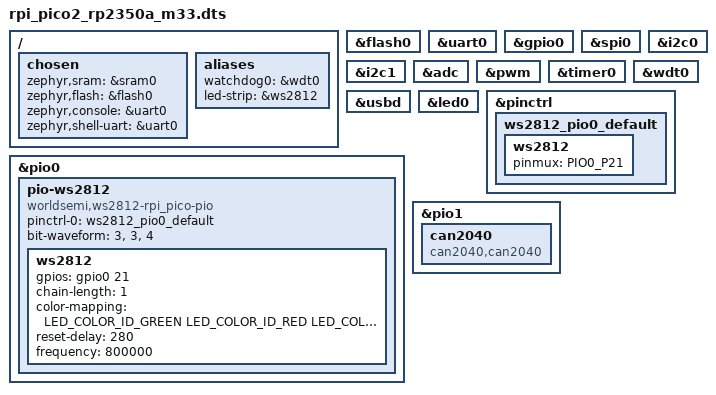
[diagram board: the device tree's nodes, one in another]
/*
 * Copyright (c) 2024 Andrew Featherstone
 *
 * SPDX-License-Identifier: Apache-2.0
 */

/dts-v1/;

/* The build system assumes that there's a cpucluster-specific file.
 *
 * This file provides composition of the device tree:
 * 1. The common features of the SoC
 * 2. Core-specific configuration.
 * 3. Board-specific configuration.
 */
#include <raspberrypi/rpi_pico/rp2350a.dtsi>
#include <raspberrypi/rpi_pico/m33.dtsi>

/* there's nothing specific to the Cortex-M33 cores vs the (not yet
 * implemented) Hazard3 cores.
 */
#include "rpi_pico2.dtsi"

/ {
	chosen {
		zephyr,sram = &sram0;
		zephyr,flash = &flash0;
		zephyr,console = &uart0;
		zephyr,shell-uart = &uart0;
	};

	aliases {
		watchdog0 = &wdt0;
		led-strip = &ws2812;
	};
};

&flash0 {
	status = "okay";
};

&uart0 {
	status = "okay";
};

gpio0_lo: &gpio0 {
	status = "okay";
};

&spi0 {
	status = "okay";
};

&i2c0 {
	status = "okay";
};

&i2c1 {
	status = "okay";
};

&adc {
	status = "okay";
};

&pwm {
	status = "okay";
};

&timer0 {
	status = "okay";
};

&wdt0 {
	status = "okay";
};

zephyr_udc0: &usbd {
	status = "okay";
};

&led0 {
	status = "okay";
};

#include <zephyr/dt-bindings/led/led.h>

&pinctrl {
	ws2812_pio0_default: ws2812_pio0_default {
		ws2812 {
				pinmux = <PIO0_P21>;
		};
	};
};

&pio0 {
		status = "okay";

		pio-ws2812 {
				compatible = "worldsemi,ws2812-rpi_pico-pio";
				status = "okay";
				pinctrl-0 = <&ws2812_pio0_default>;
				pinctrl-names = "default";
				bit-waveform = <3>, <3>, <4>;

				ws2812: ws2812 {
						status = "okay";
						gpios = <&gpio0 21 GPIO_ACTIVE_HIGH>;
						chain-length = <1>;
						color-mapping = <LED_COLOR_ID_GREEN
											LED_COLOR_ID_RED
											LED_COLOR_ID_BLUE>;
						reset-delay = <280>;
						frequency = <800000>;
				};
		};
};

&pio1 {
		status = "okay";

		can2040: can2040 {
				compatible = "can2040,can2040";
				status = "okay";
		};
};
